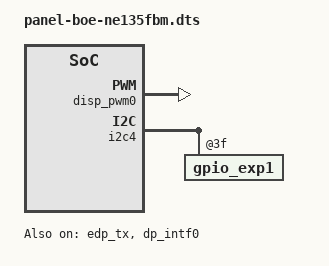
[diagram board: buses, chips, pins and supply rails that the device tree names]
/dts-v1/;
/plugin/;

#include <dt-bindings/pinctrl/mt8195-pinfunc.h>

/ {
	fragment@0 {
		target = <&edp_tx>;
		__overlay__ {
			status = "okay";
		};
	};

	fragment@1 {
		target = <&dp_intf0>;
		__overlay__ {
			status = "okay";
		};
	};

	fragment@2 {
		target-path = "/";
		__overlay__ {
			edp_panel: panel {
				status = "okay";
			};
		};
	};

	fragment@3 {
		target = <&backlight_lcd0>;
		__overlay__ {
			default-on;
		};
	};

	fragment@4 {
		target = <&disp_pwm0>;
		__overlay__ {
			status = "okay";
		};
	};

	fragment@5 {
		target = <&i2c4>;
		__overlay__ {
			gpio_exp1@3f {
				pinctrl-0 = <&gpio_exp1_pins &pri_disp_p0_3v3_sel2 &usb0_en_oc &usb1_en_oc &usb_hub_3v3_rst_n &usb_eth1_3v3_rst_n &wifi_powerdown &cam2_pwr_en &cam2_led_en &pcie_3v3_sel &bt_uart_rst_n &usb_uart_rst_n>;
			};
		};
	};

};
